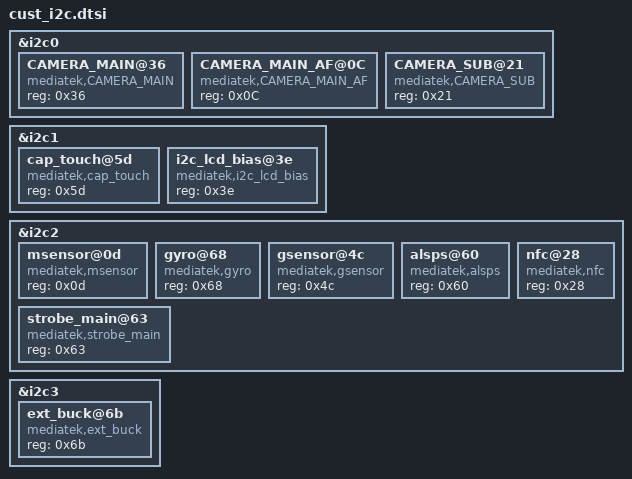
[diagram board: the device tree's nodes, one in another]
/*
 * Generated by MTK SP Drv_CodeGen Version 03.13.6  for MT6735. Copyright MediaTek Inc. (C) 2013.
 * Thu Jun  4 21:49:55 2015
 * Do Not Modify the File.
 */

/*************************
 * I2C dtsi file
*************************/

&i2c0 {
	CAMERA_MAIN@36 {
		compatible = "mediatek,CAMERA_MAIN";
		reg = <0x36>;
	};

	CAMERA_MAIN_AF@0C {
		compatible = "mediatek,CAMERA_MAIN_AF";
		reg = <0x0C>;
	};

	CAMERA_SUB@21 {
		compatible = "mediatek,CAMERA_SUB";
		reg = <0x21>;
	};

};

&i2c1 {
	cap_touch@5d {
		compatible = "mediatek,cap_touch";
		reg = <0x5d>;
	};

	i2c_lcd_bias@3e {
		compatible = "mediatek,i2c_lcd_bias";
		reg = <0x3e>;
	};

};

&i2c2 {
	msensor@0d {
		compatible = "mediatek,msensor";
		reg = <0x0d>;
	};

	gyro@68 {
		compatible = "mediatek,gyro";
		reg = <0x68>;
	};

	gsensor@4c {
		compatible = "mediatek,gsensor";
		reg = <0x4c>;
	};

	alsps@60 {
		compatible = "mediatek,alsps";
		reg = <0x60>;
	};

	nfc@28 {
		compatible = "mediatek,nfc";
		reg = <0x28>;
	};

	strobe_main@63 {
		compatible = "mediatek,strobe_main";
		reg = <0x63>;
	};

};

&i2c3 {
	ext_buck@6b {
		compatible = "mediatek,ext_buck";
		reg = <0x6b>;
	};

};

